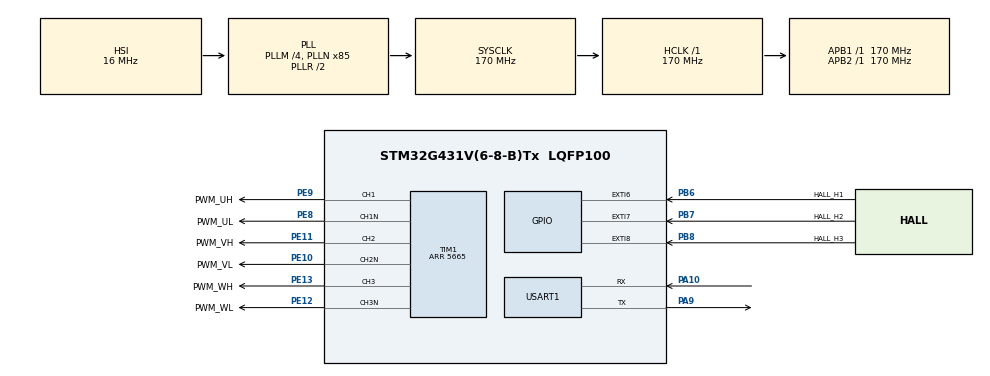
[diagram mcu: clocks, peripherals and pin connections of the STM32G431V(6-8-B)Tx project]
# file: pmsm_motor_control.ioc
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Mcu.Family=STM32G4
Mcu.Name=STM32G431V(6-8-B)Tx
Mcu.Package=LQFP100
NVIC.EXTI9_5_IRQn=true\:0\:0\:false\:false\:true\:true\:true\:true
NVIC.PriorityGroup=NVIC_PRIORITYGROUP_4
NVIC.TIM1_BRK_TIM15_IRQn=true\:0\:0\:false\:false\:true\:true\:true\:true
NVIC.TIM1_UP_TIM16_IRQn=true\:0\:0\:false\:false\:true\:true\:true\:true
NVIC.TIM3_IRQn=true\:0\:0\:false\:false\:true\:true\:true\:true
NVIC.TIM4_IRQn=true\:0\:0\:false\:false\:true\:true\:true\:true
PA10.Mode=Asynchronous
PA10.Signal=USART1_RX
PA13.Mode=Trace_Asynchronous_SW
PA13.Signal=SYS_JTMS-SWDIO
PA14.Mode=Trace_Asynchronous_SW
PA14.Signal=SYS_JTCK-SWCLK
PA9.Mode=Asynchronous
PA9.Signal=USART1_TX
PB3.Mode=Trace_Asynchronous_SW
PB3.Signal=SYS_JTDO-SWO
PB6.GPIO_Label=HALL_H1
PB6.GPIO_ModeDefaultEXTI=GPIO_MODE_IT_RISING_FALLING
PB6.Signal=GPXTI6
PB7.GPIO_Label=HALL_H2
PB7.GPIO_ModeDefaultEXTI=GPIO_MODE_IT_RISING_FALLING
PB7.Signal=GPXTI7
PB8-BOOT0.GPIO_Label=HALL_H3
PB8-BOOT0.GPIO_ModeDefaultEXTI=GPIO_MODE_IT_RISING_FALLING
PB8-BOOT0.Signal=GPXTI8
PE10.GPIO_Label=PWM_VL
PE10.Mode=PWM Generation2 CH2 CH2N
PE10.Signal=TIM1_CH2N
PE11.GPIO_Label=PWM_VH
PE11.Signal=S_TIM1_CH2
PE12.GPIO_Label=PWM_WL
PE12.Mode=PWM Generation3 CH3 CH3N
PE12.Signal=TIM1_CH3N
PE13.GPIO_Label=PWM_WH
PE13.Signal=S_TIM1_CH3
PE8.GPIO_Label=PWM_UL
PE8.Mode=PWM Generation1 CH1 CH1N
PE8.Signal=TIM1_CH1N
PE9.GPIO_Label=PWM_UH
PE9.Signal=S_TIM1_CH1
ProjectManager.HeapSize=0x200
ProjectManager.StackSize=0x400
ProjectManager.TargetToolchain=STM32CubeIDE
RCC.ADC12Freq_Value=170000000
RCC.AHBFreq_Value=170000000
RCC.APB1Freq_Value=170000000
RCC.APB1TimFreq_Value=170000000
RCC.APB2Freq_Value=170000000
RCC.APB2TimFreq_Value=170000000
RCC.CortexFreq_Value=170000000
RCC.EXTERNAL_CLOCK_VALUE=12288000
RCC.HCLKFreq_Value=170000000
RCC.HSE_VALUE=8000000
RCC.HSI48_VALUE=48000000
RCC.HSI_VALUE=16000000
RCC.LSE_VALUE=32768
RCC.PLLM=RCC_PLLM_DIV4
RCC.PLLN=85
RCC.SYSCLKFreq_VALUE=170000000
RCC.SYSCLKSource=RCC_SYSCLKSOURCE_PLLCLK
RCC.USBFreq_Value=170000000
RCC.VCOOutputFreq_Value=340000000
SH.S_TIM1_CH1.0=TIM1_CH1,PWM Generation1 CH1 CH1N
SH.S_TIM1_CH2.0=TIM1_CH2,PWM Generation2 CH2 CH2N
SH.S_TIM1_CH3.0=TIM1_CH3,PWM Generation3 CH3 CH3N
TIM1.Channel-PWM\ Generation1\ CH1\ CH1N=TIM_CHANNEL_1
TIM1.Channel-PWM\ Generation2\ CH2\ CH2N=TIM_CHANNEL_2
TIM1.Channel-PWM\ Generation3\ CH3\ CH3N=TIM_CHANNEL_3
TIM1.DeadTime=127
TIM1.PeriodNoDither=5665
TIM3.Prescaler=170-1
TIM4.PeriodNoDither=0
TIM4.Prescaler=170-1
USART1.VirtualMode-Asynchronous=VM_ASYNC
VP_SYS_VS_DBSignals.Mode=DisableDeadBatterySignals
VP_TIM1_VS_ClockSourceINT.Mode=Internal
VP_TIM3_VS_ClockSourceINT.Mode=Internal
VP_TIM4_VS_ClockSourceINT.Mode=Internal
board=custom

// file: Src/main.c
/* USER CODE BEGIN Header */
/**
  ******************************************************************************
  * @file           : main.c
  * @brief          : Main program body
  ******************************************************************************
  * @attention
  *
  * Copyright (c) 2024 STMicroelectronics.
  * All rights reserved.
  *
  * This software is licensed under terms that can be found in the LICENSE file
  * in the root directory of this software component.
  * If no LICENSE file comes with this software, it is provided AS-IS.
  *
  ******************************************************************************
  */
/* USER CODE END Header */
#include "main.h"
#include "tim.h"
#include "usart.h"
#include "gpio.h"
#include "pmsm/pmsm.h"

/* USER CODE BEGIN Includes */
#include <stm32g4xx_ll_tim.h>
#include <stdio.h>
/* USER CODE END Includes */

void SystemClock_Config(void);

int main(void)
{
  /* USER CODE BEGIN 1 */
	setbuf(stdout, NULL);
  /* USER CODE END 1 */

  /* MCU Configuration--------------------------------------------------------*/

  /* Reset of all peripherals, Initializes the Flash interface and the Systick. */
  HAL_Init();

  /* Configure the system clock */
  SystemClock_Config();

  /* Initialize all configured peripherals */
  MX_GPIO_Init();
  MX_TIM1_Init();
  MX_USART1_UART_Init();
  MX_TIM4_Init();
  MX_TIM3_Init();
  /* USER CODE BEGIN 2 */

  pmsm_init();
  PMSM_MotorSetSpin( PMSM_CCW );
  HAL_Delay( 3000 );

  printf( ">> Started\r\n" );
  pmsm_motor_commutation( pmsm_hall_sensors_get_position() );
  pmsm_motor_set_run();
  /* USER CODE END 2 */

  /* Infinite loop */
  while (1)
  {

    /* USER CODE BEGIN 3 */
	  pmsm_set_PWM( 5000 );
  }
  /* USER CODE END 3 */
}

void SystemClock_Config(void)
{
  RCC_OscInitTypeDef RCC_OscInitStruct = {0};
  RCC_ClkInitTypeDef RCC_ClkInitStruct = {0};

  /** Configure the main internal regulator output voltage
  */
  HAL_PWREx_ControlVoltageScaling(PWR_REGULATOR_VOLTAGE_SCALE1_BOOST);

  /** Initializes the RCC Oscillators according to the specified parameters
  * in the RCC_OscInitTypeDef structure.
  */
  RCC_OscInitStruct.OscillatorType = RCC_OSCILLATORTYPE_HSI;
  RCC_OscInitStruct.HSIState = RCC_HSI_ON;
  RCC_OscInitStruct.HSICalibrationValue = RCC_HSICALIBRATION_DEFAULT;
  RCC_OscInitStruct.PLL.PLLState = RCC_PLL_ON;
  RCC_OscInitStruct.PLL.PLLSource = RCC_PLLSOURCE_HSI;
  RCC_OscInitStruct.PLL.PLLM = RCC_PLLM_DIV4;
  RCC_OscInitStruct.PLL.PLLN = 85;
  RCC_OscInitStruct.PLL.PLLP = RCC_PLLP_DIV2;
  RCC_OscInitStruct.PLL.PLLQ = RCC_PLLQ_DIV2;
  RCC_OscInitStruct.PLL.PLLR = RCC_PLLR_DIV2;
  if (HAL_RCC_OscConfig(&RCC_OscInitStruct) != HAL_OK)
  {
    Error_Handler();
  }

  /** Initializes the CPU, AHB and APB buses clocks
  */
  RCC_ClkInitStruct.ClockType = RCC_CLOCKTYPE_HCLK|RCC_CLOCKTYPE_SYSCLK
                              |RCC_CLOCKTYPE_PCLK1|RCC_CLOCKTYPE_PCLK2;
  RCC_ClkInitStruct.SYSCLKSource = RCC_SYSCLKSOURCE_PLLCLK;
  RCC_ClkInitStruct.AHBCLKDivider = RCC_SYSCLK_DIV1;
  RCC_ClkInitStruct.APB1CLKDivider = RCC_HCLK_DIV1;
  RCC_ClkInitStruct.APB2CLKDivider = RCC_HCLK_DIV1;

  if (HAL_RCC_ClockConfig(&RCC_ClkInitStruct, FLASH_LATENCY_4) != HAL_OK)
  {
    Error_Handler();
  }
}

void Error_Handler(void)
{
  __disable_irq();
  while (1)
  {
  }
}
